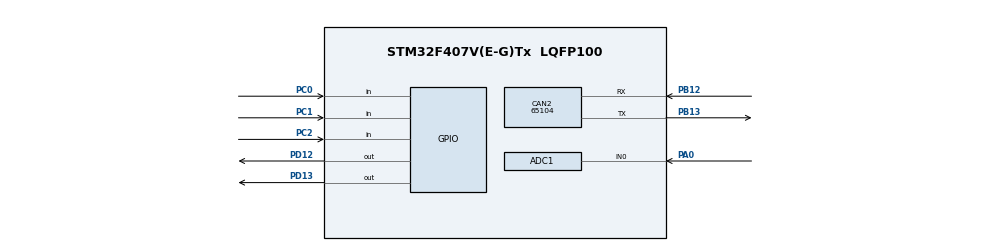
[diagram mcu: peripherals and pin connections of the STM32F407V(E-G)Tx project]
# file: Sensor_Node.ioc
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ADC1.Channel-0\#ChannelRegularConversion=ADC_CHANNEL_0
ADC1.NbrOfConversionFlag=1
ADC1.Rank-0\#ChannelRegularConversion=1
ADC1.SamplingTime-0\#ChannelRegularConversion=ADC_SAMPLETIME_3CYCLES
ADC1.master=1
CAN2.CalculateBaudRate=65104
CAN2.CalculateTimeBit=15360
CAN2.CalculateTimeQuantum=5120.0
Mcu.Family=STM32F4
Mcu.Name=STM32F407V(E-G)Tx
Mcu.Package=LQFP100
NVIC.ADC_IRQn=true\:0\:0\:false\:false\:true\:true\:true\:true
NVIC.CAN2_RX0_IRQn=true\:0\:0\:false\:false\:true\:true\:true\:true
NVIC.PriorityGroup=NVIC_PRIORITYGROUP_0
PA0-WKUP.Signal=ADCx_IN0
PB12.Mode=CAN_Activate
PB12.Signal=CAN2_RX
PB13.Mode=CAN_Activate
PB13.Signal=CAN2_TX
PC0.Signal=GPIO_Input
PC1.Signal=GPIO_Input
PC2.Signal=GPIO_Input
PD12.Signal=GPIO_Output
PD13.Signal=GPIO_Output
ProjectManager.HeapSize=0x200
ProjectManager.StackSize=0x400
ProjectManager.TargetToolchain=STM32CubeIDE
RCC.48MHZClocksFreq_Value=14285714.285714285
RCC.AHBFreq_Value=25000000
RCC.APB1CLKDivider=RCC_HCLK_DIV8
RCC.APB1Freq_Value=3125000
RCC.APB1TimFreq_Value=6250000
RCC.APB2CLKDivider=RCC_HCLK_DIV4
RCC.APB2Freq_Value=6250000
RCC.APB2TimFreq_Value=12500000
RCC.CortexFreq_Value=25000000
RCC.HCLKFreq_Value=25000000
RCC.HSE_VALUE=8000000
RCC.HSI_VALUE=16000000
RCC.LSE_VALUE=32768
RCC.PLLM=8
RCC.PLLN=50
RCC.PLLP=RCC_PLLP_DIV4
RCC.PLLQ=7
RCC.SYSCLKFreq_VALUE=25000000
RCC.SYSCLKSource=RCC_SYSCLKSOURCE_PLLCLK
RCC.VCOOutputFreq_Value=100000000
SH.ADCx_IN0.0=ADC1_IN0,IN0
board=STM32F407G-DISC1

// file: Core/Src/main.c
#include "main.h"
#include "gpio.h"
#include "can.h"
#include "adc.h"

/* REQUIRED prototype (CubeMX provides definition elsewhere) */
void SystemClock_Config(void);

/* USER CODE BEGIN PV */
CAN_TxHeaderTypeDef TxHeader;
uint32_t TxMailbox;
uint8_t TxData[3];
/* USER CODE END PV */

void CAN_Filter_Config(void);

int main(void)
{
  HAL_Init();

  SystemClock_Config();

  MX_GPIO_Init();
  MX_CAN2_Init();
  MX_ADC1_Init();

  /* CAN Filter */
  CAN_Filter_Config();

  HAL_CAN_Start(&hcan2);

  /* CAN Header */
  TxHeader.StdId = 0x123;
  TxHeader.ExtId = 0x00;
  TxHeader.IDE   = CAN_ID_STD;
  TxHeader.RTR   = CAN_RTR_DATA;
  TxHeader.DLC   = 3;
  TxHeader.TransmitGlobalTime = DISABLE;

  while (1)
  {
    uint16_t adc_value;
    uint8_t alcohol, vibration, seatbelt;

    seatbelt  = HAL_GPIO_ReadPin(GPIOC, GPIO_PIN_0);
    vibration = HAL_GPIO_ReadPin(GPIOC, GPIO_PIN_1);

    HAL_ADC_Start(&hadc1);
    HAL_ADC_PollForConversion(&hadc1, 10);
    adc_value = HAL_ADC_GetValue(&hadc1);
    HAL_ADC_Stop(&hadc1);

    alcohol = (adc_value > 2000) ? 1 : 0;

    TxData[0] = seatbelt;
    TxData[1] = vibration;
    TxData[2] = alcohol;

    if (HAL_CAN_GetTxMailboxesFreeLevel(&hcan2) > 0)
    {
      HAL_CAN_AddTxMessage(&hcan2, &TxHeader, TxData, &TxMailbox);
    }

    HAL_Delay(500);
  }
}

/* CAN Filter Configuration */
void CAN_Filter_Config(void)
{
  CAN_FilterTypeDef filter;

  filter.FilterActivation = ENABLE;
  filter.FilterBank = 0;
  filter.FilterFIFOAssignment = CAN_FILTER_FIFO0;
  filter.FilterIdHigh = 0x123 << 5;
  filter.FilterIdLow = 0x0000;
  filter.FilterMaskIdHigh = 0x7FF << 5;
  filter.FilterMaskIdLow = 0x0000;
  filter.FilterMode = CAN_FILTERMODE_IDMASK;
  filter.FilterScale = CAN_FILTERSCALE_32BIT;

  HAL_CAN_ConfigFilter(&hcan2, &filter);
}
